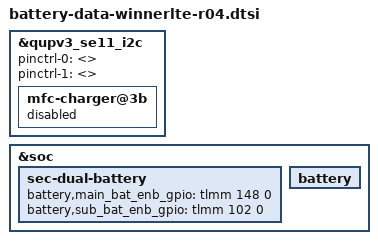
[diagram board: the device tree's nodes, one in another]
/*
 * SAMSUNG board device tree source
 *
 * Copyright (c) 2018 Samsung Electronics Co., Ltd.
 *		http://www.samsung.com
 *
 * This program is free software; you can redistribute it and/or modify
 * it under the terms of the GNU General Public License version 2 as
 * published by the Free Software Foundation.
 */
/* This dtsi is for hw rev from 04 to 05 */
#include "battery-data-winnerlte-common.dtsi"

&qupv3_se11_i2c { 
	pinctrl-0 = <>;
	pinctrl-1 = <>;

	mfc-charger@3b {
		status = "disabled";
	};
};

&soc {

	sec-dual-battery {
		battery,main_bat_enb_gpio = <&tlmm 148 0>;
		battery,sub_bat_enb_gpio = <&tlmm 102 0>;
	};

	battery {
		/delete-property/ battery,wireless_charger_name;
		/delete-property/ battery,wpc_det;
		/delete-property/ battery,wpc_en;
	};
};
